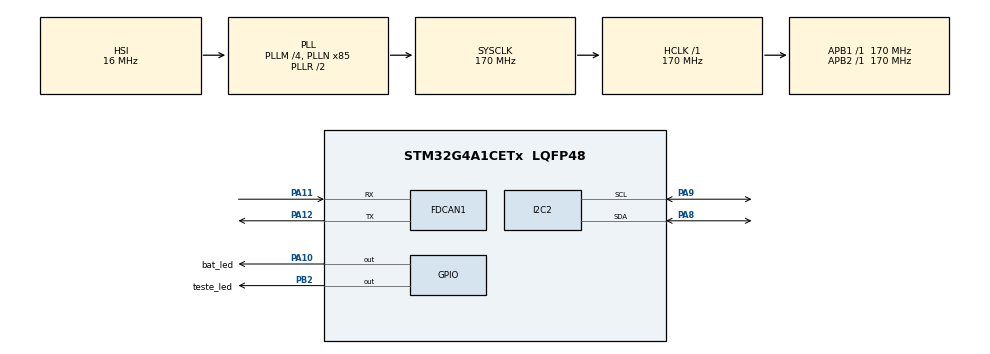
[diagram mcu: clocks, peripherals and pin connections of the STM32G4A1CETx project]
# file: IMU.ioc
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Dma.I2C2_RX.0.Direction=DMA_PERIPH_TO_MEMORY
Dma.I2C2_RX.0.EventEnable=DISABLE
Dma.I2C2_RX.0.Instance=DMA1_Channel1
Dma.I2C2_RX.0.MemDataAlignment=DMA_MDATAALIGN_BYTE
Dma.I2C2_RX.0.MemInc=DMA_MINC_ENABLE
Dma.I2C2_RX.0.Mode=DMA_NORMAL
Dma.I2C2_RX.0.PeriphDataAlignment=DMA_PDATAALIGN_BYTE
Dma.I2C2_RX.0.PeriphInc=DMA_PINC_DISABLE
Dma.I2C2_RX.0.Polarity=HAL_DMAMUX_REQ_GEN_RISING
Dma.I2C2_RX.0.Priority=DMA_PRIORITY_LOW
Dma.I2C2_RX.0.RequestNumber=1
Dma.I2C2_RX.0.SignalID=NONE
Dma.I2C2_RX.0.SyncEnable=DISABLE
Dma.I2C2_RX.0.SyncPolarity=HAL_DMAMUX_SYNC_NO_EVENT
Dma.I2C2_RX.0.SyncRequestNumber=1
Dma.I2C2_RX.0.SyncSignalID=NONE
Dma.Request0=I2C2_RX
FDCAN1.CalculateBaudRateNominal=250000
FDCAN1.CalculateTimeBitNominal=4000
FDCAN1.CalculateTimeQuantumNominal=200.0
FDCAN1.NominalPrescaler=34
FDCAN1.NominalTimeSeg1=15
FDCAN1.NominalTimeSeg2=4
FDCAN1.TransmitPause=DISABLE
I2C2.Timing=0x40B285C2
Mcu.Family=STM32G4
Mcu.Name=STM32G4A1CETx
Mcu.Package=LQFP48
NVIC.DMA1_Channel1_IRQn=true\:0\:0\:false\:false\:true\:false\:true\:true
NVIC.FDCAN1_IT0_IRQn=true\:0\:0\:false\:false\:true\:true\:true\:true
NVIC.FDCAN1_IT1_IRQn=true\:0\:0\:false\:false\:true\:true\:true\:true
NVIC.PriorityGroup=NVIC_PRIORITYGROUP_4
NVIC.TIM3_IRQn=true\:0\:0\:false\:false\:true\:true\:true\:true
PA10.GPIO_Label=bat_led
PA10.PinState=GPIO_PIN_SET
PA10.Signal=GPIO_Output
PA11.Mode=FDCAN_Activate
PA11.Signal=FDCAN1_RX
PA12.Mode=FDCAN_Activate
PA12.Signal=FDCAN1_TX
PA13.Mode=Serial_Wire
PA13.Signal=SYS_JTMS-SWDIO
PA14.Mode=Serial_Wire
PA14.Signal=SYS_JTCK-SWCLK
PA8.GPIO_Pu=GPIO_PULLUP
PA8.Mode=I2C
PA8.Signal=I2C2_SDA
PA9.GPIO_Pu=GPIO_PULLUP
PA9.Mode=I2C
PA9.Signal=I2C2_SCL
PB2.GPIO_Label=teste_led
PB2.PinState=GPIO_PIN_SET
PB2.Signal=GPIO_Output
PF0-OSC_IN.Mode=HSE-External-Oscillator
PF0-OSC_IN.Signal=RCC_OSC_IN
PF1-OSC_OUT.Mode=HSE-External-Oscillator
PF1-OSC_OUT.Signal=RCC_OSC_OUT
ProjectManager.HeapSize=0x200
ProjectManager.StackSize=0x400
ProjectManager.TargetToolchain=STM32CubeIDE
RCC.ADC12Freq_Value=170000000
RCC.ADC345Freq_Value=170000000
RCC.AHBFreq_Value=170000000
RCC.APB1Freq_Value=170000000
RCC.APB1TimFreq_Value=170000000
RCC.APB2Freq_Value=170000000
RCC.APB2TimFreq_Value=170000000
RCC.CortexFreq_Value=170000000
RCC.EXTERNAL_CLOCK_VALUE=12288000
RCC.HCLKFreq_Value=170000000
RCC.HSE_VALUE=8000000
RCC.HSI48_VALUE=48000000
RCC.HSI_VALUE=16000000
RCC.LSE_VALUE=32768
RCC.PLLM=RCC_PLLM_DIV4
RCC.PLLN=85
RCC.SYSCLKFreq_VALUE=170000000
RCC.SYSCLKSource=RCC_SYSCLKSOURCE_PLLCLK
RCC.VCOOutputFreq_Value=340000000
TIM3.PeriodNoDither=9999
TIM3.Prescaler=1699
VP_SYS_VS_DBSignals.Mode=DisableDeadBatterySignals
VP_TIM3_VS_ClockSourceINT.Mode=Internal
board=custom

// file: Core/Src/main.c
/* USER CODE BEGIN Header */
/**
  ******************************************************************************
  * @file           : main.c
  * @brief          : Main program body
  ******************************************************************************
  * @attention
  *
  * Copyright (c) 2025 STMicroelectronics.
  * All rights reserved.
  *
  * This software is licensed under terms that can be found in the LICENSE file
  * in the root directory of this software component.
  * If no LICENSE file comes with this software, it is provided AS-IS.
  *
  ******************************************************************************
  */
/* USER CODE END Header */
#include "main.h"
#include "dma.h"
#include "fdcan.h"
#include "i2c.h"
#include "tim.h"
#include "gpio.h"

/* USER CODE BEGIN Includes */
#include "LSM6.h"
#include "cant.h"
/* USER CODE END Includes */

void SystemClock_Config(void);

/* USER CODE BEGIN 0 */

void HAL_TIM_PeriodElapsedCallback(TIM_HandleTypeDef *htim){
	if(htim == &htim3){
		can_enviar();
	}
}
/* USER CODE END 0 */

int main(void)
{

  /* MCU Configuration--------------------------------------------------------*/

  /* Reset of all peripherals, Initializes the Flash interface and the Systick. */
  HAL_Init();

  /* Configure the system clock */
  SystemClock_Config();

  /* Initialize all configured peripherals */
  MX_GPIO_Init();
  MX_DMA_Init();
  MX_I2C2_Init();
  MX_FDCAN1_Init();
  MX_TIM3_Init();
  /* USER CODE BEGIN 2 */

  lsmReady = lsm6_Init();
  HAL_FDCAN_Start(&hfdcan1);
  HAL_TIM_Base_Start_IT(&htim3);

  /* USER CODE END 2 */

  /* Infinite loop */
  while (1)
  {

    /* USER CODE BEGIN 3 */
	  if(lsmReady){
		  lsm6_Read();
		  //lsm6_DataParsing();
	  }

  }
  /* USER CODE END 3 */
}

void SystemClock_Config(void)
{
  RCC_OscInitTypeDef RCC_OscInitStruct = {0};
  RCC_ClkInitTypeDef RCC_ClkInitStruct = {0};

  /** Configure the main internal regulator output voltage
  */
  HAL_PWREx_ControlVoltageScaling(PWR_REGULATOR_VOLTAGE_SCALE1_BOOST);

  /** Initializes the RCC Oscillators according to the specified parameters
  * in the RCC_OscInitTypeDef structure.
  */
  RCC_OscInitStruct.OscillatorType = RCC_OSCILLATORTYPE_HSI;
  RCC_OscInitStruct.HSIState = RCC_HSI_ON;
  RCC_OscInitStruct.HSICalibrationValue = RCC_HSICALIBRATION_DEFAULT;
  RCC_OscInitStruct.PLL.PLLState = RCC_PLL_ON;
  RCC_OscInitStruct.PLL.PLLSource = RCC_PLLSOURCE_HSI;
  RCC_OscInitStruct.PLL.PLLM = RCC_PLLM_DIV4;
  RCC_OscInitStruct.PLL.PLLN = 85;
  RCC_OscInitStruct.PLL.PLLP = RCC_PLLP_DIV2;
  RCC_OscInitStruct.PLL.PLLQ = RCC_PLLQ_DIV2;
  RCC_OscInitStruct.PLL.PLLR = RCC_PLLR_DIV2;
  if (HAL_RCC_OscConfig(&RCC_OscInitStruct) != HAL_OK)
  {
    Error_Handler();
  }

  /** Initializes the CPU, AHB and APB buses clocks
  */
  RCC_ClkInitStruct.ClockType = RCC_CLOCKTYPE_HCLK|RCC_CLOCKTYPE_SYSCLK
                              |RCC_CLOCKTYPE_PCLK1|RCC_CLOCKTYPE_PCLK2;
  RCC_ClkInitStruct.SYSCLKSource = RCC_SYSCLKSOURCE_PLLCLK;
  RCC_ClkInitStruct.AHBCLKDivider = RCC_SYSCLK_DIV1;
  RCC_ClkInitStruct.APB1CLKDivider = RCC_HCLK_DIV1;
  RCC_ClkInitStruct.APB2CLKDivider = RCC_HCLK_DIV1;

  if (HAL_RCC_ClockConfig(&RCC_ClkInitStruct, FLASH_LATENCY_4) != HAL_OK)
  {
    Error_Handler();
  }
}

void Error_Handler(void)
{
  __disable_irq();
  while (1)
  {
  }
}
